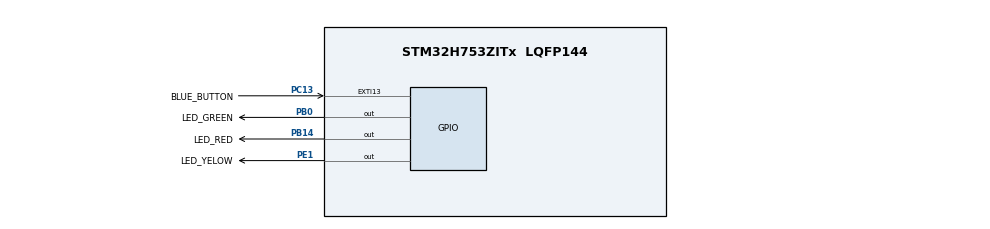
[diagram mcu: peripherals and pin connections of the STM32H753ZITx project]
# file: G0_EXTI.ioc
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CORTEX_M7.default_mode_Activation=1
Mcu.Family=STM32H7
Mcu.Name=STM32H753ZITx
Mcu.Package=LQFP144
NVIC.EXTI15_10_IRQn=true\:0\:0\:false\:false\:true\:true\:true\:true
NVIC.PriorityGroup=NVIC_PRIORITYGROUP_4
PB0.GPIO_Label=LED_GREEN
PB0.Signal=GPIO_Output
PB14.GPIO_Label=LED_RED
PB14.Signal=GPIO_Output
PC13.GPIO_Label=BLUE_BUTTON
PC13.GPIO_ModeDefaultEXTI=GPIO_MODE_IT_FALLING
PC13.Signal=GPXTI13
PE1.GPIO_Label=LED_YELOW
PE1.Signal=GPIO_Output
ProjectManager.HeapSize=0x200
ProjectManager.StackSize=0x400
ProjectManager.TargetToolchain=STM32CubeIDE
RCC.ADCFreq_Value=129000000
RCC.APB1Freq_Value=64000000
RCC.APB2Freq_Value=64000000
RCC.APB3Freq_Value=64000000
RCC.APB4Freq_Value=64000000
RCC.CortexFreq_Value=64000000
RCC.HCLKFreq_Value=64000000
RCC.SYSCLKFreq_VALUE=64000000
RCC.USBFreq_Value=129000000
VP_MEMORYMAP_VS_MEMORYMAP.Mode=CurAppReg
board=custom

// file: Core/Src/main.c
/* USER CODE BEGIN Header */
/**
  ******************************************************************************
  * @file           : main.c
  * @brief          : Main program body
  ******************************************************************************
  * @attention
  *
  * Copyright (c) 2025 STMicroelectronics.
  * All rights reserved.
  *
  * This software is licensed under terms that can be found in the LICENSE file
  * in the root directory of this software component.
  * If no LICENSE file comes with this software, it is provided AS-IS.
  *
  ******************************************************************************
  */
/* USER CODE END Header */
#include "main.h"

/* USER CODE BEGIN PV */
uint8_t flag=0;
/* USER CODE END PV */

void SystemClock_Config(void);
static void MPU_Config(void);
static void MX_GPIO_Init(void);

int main(void)
{

  /* MPU Configuration--------------------------------------------------------*/
   MPU_Config();

  /* MCU Configuration--------------------------------------------------------*/

  /* Reset of all peripherals, Initializes the Flash interface and the Systick. */
  LL_APB4_GRP1_EnableClock(LL_APB4_GRP1_PERIPH_SYSCFG);

  /* System interrupt init*/
  NVIC_SetPriorityGrouping(NVIC_PRIORITYGROUP_4);

  /* SysTick_IRQn interrupt configuration */
  NVIC_SetPriority(SysTick_IRQn, NVIC_EncodePriority(NVIC_GetPriorityGrouping(),15, 0));

  /* Configure the system clock */
  SystemClock_Config();

  /* Initialize all configured peripherals */
  MX_GPIO_Init();

  /* Infinite loop */
  /* USER CODE BEGIN WHILE */
  while (1)
  {
	  if(1==flag){
		  /*HAL_GPIO_TogglePin(LED_GREEN_GPIO_Port, LED_GREEN_Pin);
		   *
		   */
		  LL_GPIO_TogglePin(LED_GREEN_GPIO_Port, LED_GREEN_Pin);

		  /*HAL_GPIO_TogglePin(LED_YELOW_GPIO_Port, LED_YELOW_Pin);
		   *
		   */
		  LL_GPIO_TogglePin(LED_YELOW_GPIO_Port, LED_YELOW_Pin);

		  /*HAL_GPIO_TogglePin(LED_RED_GPIO_Port, LED_RED_Pin);
		  HAL_Delay(300);
		  */
		  LL_GPIO_TogglePin(LED_RED_GPIO_Port, LED_RED_Pin);

		  flag=0;
	  }
    /* USER CODE END WHILE */

  }
}

void SystemClock_Config(void)
{
  LL_FLASH_SetLatency(LL_FLASH_LATENCY_1);
  while(LL_FLASH_GetLatency()!= LL_FLASH_LATENCY_1)
  {
  }
  LL_PWR_ConfigSupply(LL_PWR_LDO_SUPPLY);
  LL_PWR_SetRegulVoltageScaling(LL_PWR_REGU_VOLTAGE_SCALE3);
  while (LL_PWR_IsActiveFlag_VOS() == 0)
  {
  }
  LL_RCC_HSI_Enable();

   /* Wait till HSI is ready */
  while(LL_RCC_HSI_IsReady() != 1)
  {

  }
  LL_RCC_HSI_SetCalibTrimming(64);
  LL_RCC_HSI_SetDivider(LL_RCC_HSI_DIV1);
  LL_RCC_SetSysClkSource(LL_RCC_SYS_CLKSOURCE_HSI);

   /* Wait till System clock is ready */
  while(LL_RCC_GetSysClkSource() != LL_RCC_SYS_CLKSOURCE_STATUS_HSI)
  {

  }
  LL_RCC_SetSysPrescaler(LL_RCC_SYSCLK_DIV_1);
  LL_RCC_SetAHBPrescaler(LL_RCC_AHB_DIV_1);
  LL_RCC_SetAPB1Prescaler(LL_RCC_APB1_DIV_1);
  LL_RCC_SetAPB2Prescaler(LL_RCC_APB2_DIV_1);
  LL_RCC_SetAPB3Prescaler(LL_RCC_APB3_DIV_1);
  LL_RCC_SetAPB4Prescaler(LL_RCC_APB4_DIV_1);

  LL_Init1msTick(64000000);

  LL_SetSystemCoreClock(64000000);
}

static void MX_GPIO_Init(void)
{
  LL_EXTI_InitTypeDef EXTI_InitStruct = {0};
  LL_GPIO_InitTypeDef GPIO_InitStruct = {0};

  /* GPIO Ports Clock Enable */
  LL_AHB4_GRP1_EnableClock(LL_AHB4_GRP1_PERIPH_GPIOC);
  LL_AHB4_GRP1_EnableClock(LL_AHB4_GRP1_PERIPH_GPIOB);
  LL_AHB4_GRP1_EnableClock(LL_AHB4_GRP1_PERIPH_GPIOE);

  /**/
  LL_GPIO_ResetOutputPin(GPIOB, LED_GREEN_Pin|LED_RED_Pin);

  /**/
  LL_GPIO_ResetOutputPin(LED_YELOW_GPIO_Port, LED_YELOW_Pin);

  /**/
  LL_SYSCFG_SetEXTISource(LL_SYSCFG_EXTI_PORTC, LL_SYSCFG_EXTI_LINE13);

  /**/
  EXTI_InitStruct.Line_0_31 = LL_EXTI_LINE_13;
  EXTI_InitStruct.Line_32_63 = LL_EXTI_LINE_NONE;
  EXTI_InitStruct.Line_64_95 = LL_EXTI_LINE_NONE;
  EXTI_InitStruct.LineCommand = ENABLE;
  EXTI_InitStruct.Mode = LL_EXTI_MODE_IT;
  EXTI_InitStruct.Trigger = LL_EXTI_TRIGGER_FALLING;
  LL_EXTI_Init(&EXTI_InitStruct);

  /**/
  LL_GPIO_SetPinPull(BLUE_BUTTON_GPIO_Port, BLUE_BUTTON_Pin, LL_GPIO_PULL_NO);

  /**/
  LL_GPIO_SetPinMode(BLUE_BUTTON_GPIO_Port, BLUE_BUTTON_Pin, LL_GPIO_MODE_INPUT);

  /**/
  GPIO_InitStruct.Pin = LED_GREEN_Pin|LED_RED_Pin;
  GPIO_InitStruct.Mode = LL_GPIO_MODE_OUTPUT;
  GPIO_InitStruct.Speed = LL_GPIO_SPEED_FREQ_LOW;
  GPIO_InitStruct.OutputType = LL_GPIO_OUTPUT_PUSHPULL;
  GPIO_InitStruct.Pull = LL_GPIO_PULL_NO;
  LL_GPIO_Init(GPIOB, &GPIO_InitStruct);

  /**/
  GPIO_InitStruct.Pin = LED_YELOW_Pin;
  GPIO_InitStruct.Mode = LL_GPIO_MODE_OUTPUT;
  GPIO_InitStruct.Speed = LL_GPIO_SPEED_FREQ_LOW;
  GPIO_InitStruct.OutputType = LL_GPIO_OUTPUT_PUSHPULL;
  GPIO_InitStruct.Pull = LL_GPIO_PULL_NO;
  LL_GPIO_Init(LED_YELOW_GPIO_Port, &GPIO_InitStruct);

  /* EXTI interrupt init*/
  NVIC_SetPriority(EXTI15_10_IRQn, NVIC_EncodePriority(NVIC_GetPriorityGrouping(),0, 0));
  NVIC_EnableIRQ(EXTI15_10_IRQn);

}

/* USER CODE BEGIN 4 */

/*
void HAL_GPIO_EXTI_Callback(uint16_t GPIO_Pin)
{
flag=1;
}

*/

/* USER CODE END 4 */

 /* MPU Configuration */

void MPU_Config(void)
{

  /* Disables the MPU */
  LL_MPU_Disable();

  /** Initializes and configures the Region and the memory to be protected
  */
  LL_MPU_ConfigRegion(LL_MPU_REGION_NUMBER0, 0x87, 0x0, LL_MPU_REGION_SIZE_4GB|LL_MPU_TEX_LEVEL0|LL_MPU_REGION_NO_ACCESS|LL_MPU_INSTRUCTION_ACCESS_DISABLE|LL_MPU_ACCESS_SHAREABLE|LL_MPU_ACCESS_NOT_CACHEABLE|LL_MPU_ACCESS_NOT_BUFFERABLE);
  /* Enables the MPU */
  LL_MPU_Enable(LL_MPU_CTRL_PRIVILEGED_DEFAULT);

}

void Error_Handler(void)
{
  __disable_irq();
  while (1)
  {
  }
}
